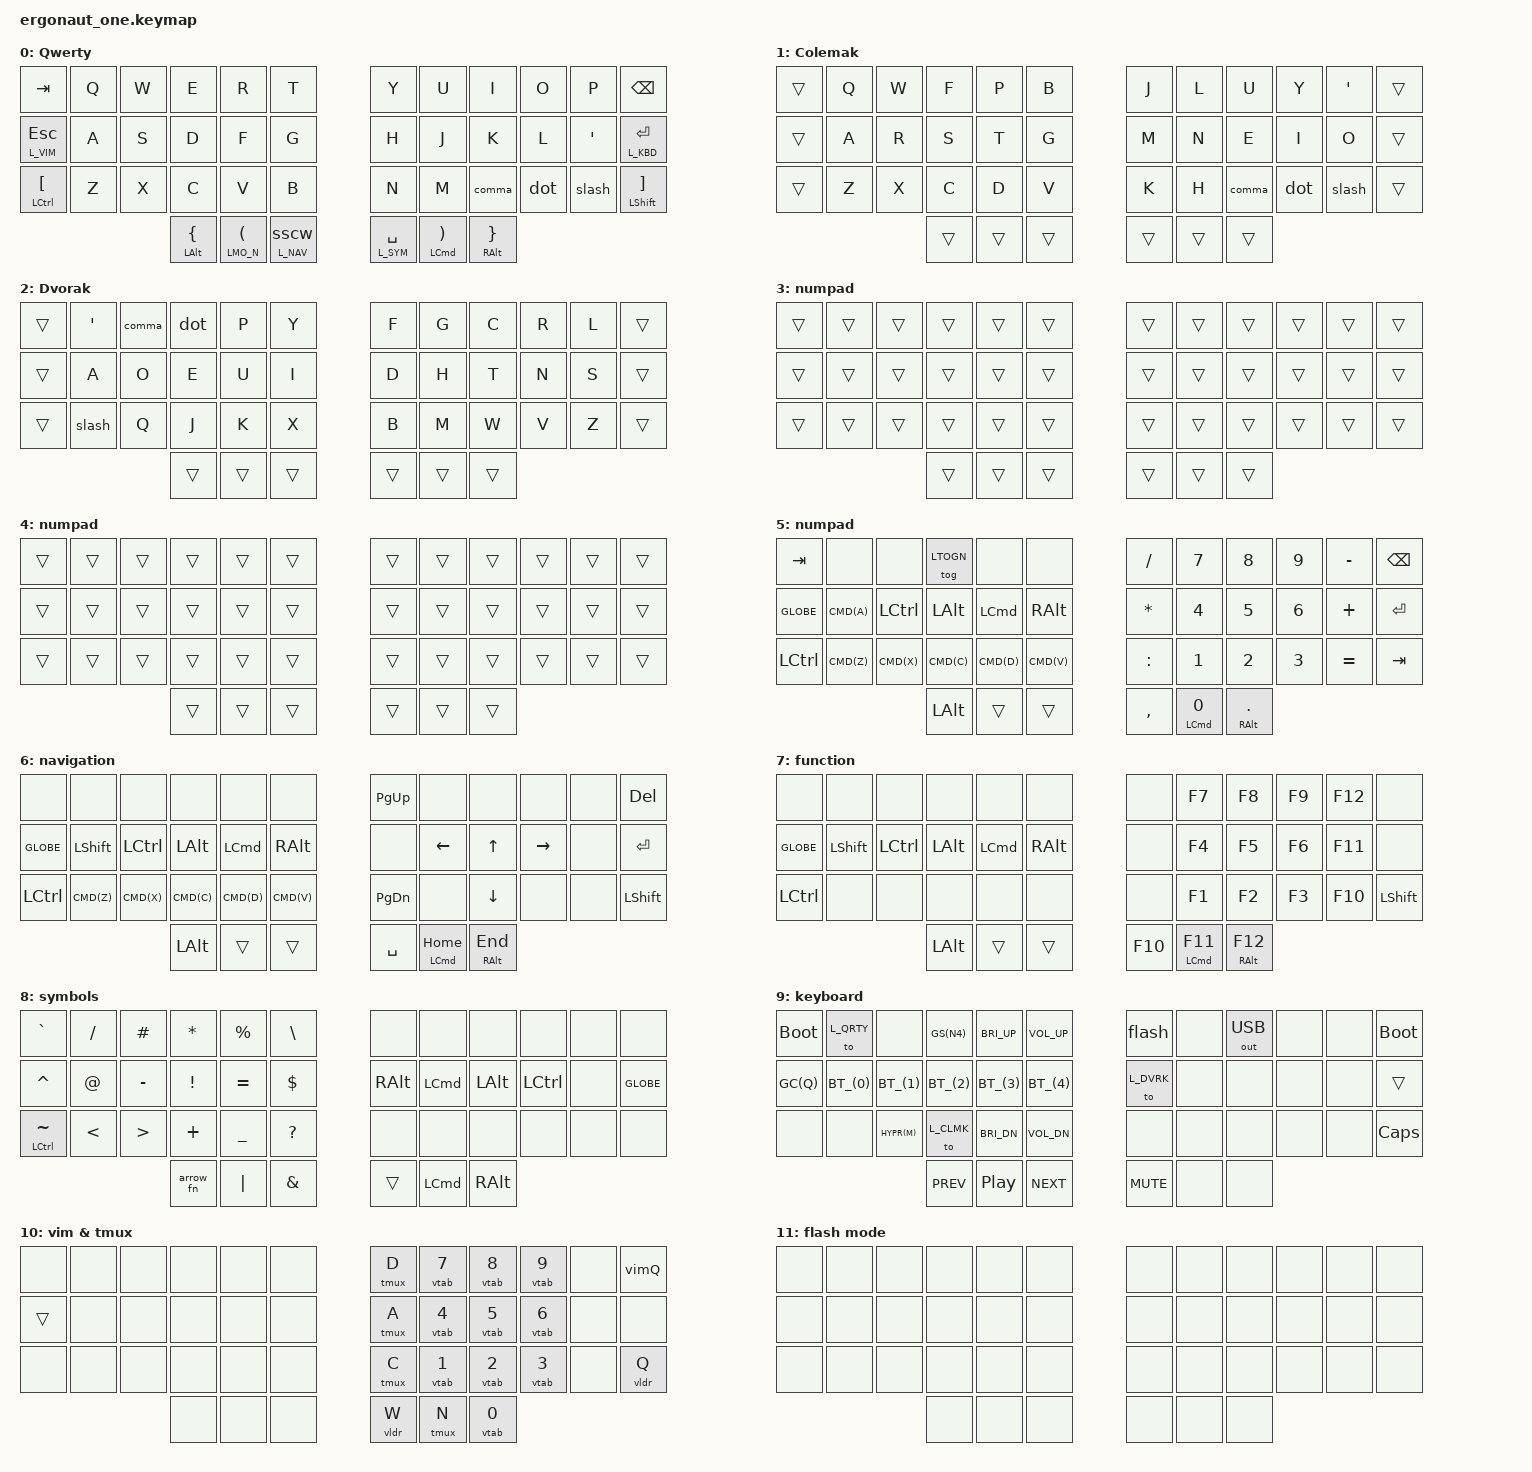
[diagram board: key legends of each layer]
#include <behaviors.dtsi>
#include <dt-bindings/zmk/bt.h>
#include <dt-bindings/zmk/keys.h>
#include <dt-bindings/zmk/outputs.h>

#define L_QRTY 0
#define L_CLMK 1
#define L_DVRK 2
#define LMO_N  3
#define LTOGN  4
#define L_NUM  5
#define L_NAV  6
#define L_FNC  7
#define L_SYM  8
#define L_KBD  9
#define L_VIM  10
#define L_BOOT 11

// transparent and none shortcuts
#define I___I &trans
#define ___ &none

// Modifier key combinations
#define CMD(key) &kp LG(key)
#define GC(key) &kp LG(LC(key))
#define GS(key) &kp LG(LS(key))
#define HYPR(key) &kp LG(LA(LC(LS(key))))

// Macro for bluetooth connections
#define BT_(btnum) &bt_key btnum btnum

&lt { quick-tap-ms = <200>; };

&mt {
    quick-tap-ms = <200>;
    require-prior-idle-ms = <150>;
    tapping-term-ms = <300>;
    flavor = "tap-preferred";
};

&sk {
    quick-release;
    release-after-ms = <2000>;
};

&caps_word { continue-list = <UNDERSCORE BACKSPACE DELETE MINUS>; };

/ {
    conditional_layers {
        compatible = "zmk,conditional-layers";

        function_combination {
            if-layers = <LMO_N L_NAV>;
            then-layer = <L_FNC>;
        };

        numpad_momentary {
            if-layers = <LMO_N>;
            then-layer = <L_NUM>;
        };

        numpad_toggle {
            if-layers = <LTOGN>;
            then-layer = <L_NUM>;
        };
    };

    macros {
        arrow_fn: arrow_fn {
            compatible = "zmk,behavior-macro";
            #binding-cells = <0>;
            bindings = <&kp EQUAL &kp GT &kp SPACE>;
        };

        bt_clr: bluetooth_clear_macro {
            compatible = "zmk,behavior-macro-one-param";
            #binding-cells = <1>;
            bindings =
                <&macro_param_1to1 &bt_sel MACRO_PLACEHOLDER>,
                <&bt BT_CLR>;
        };

        bt_sel: bluetooth_selection_macro {
            compatible = "zmk,behavior-macro-one-param";
            #binding-cells = <1>;
            bindings =
                <&out OUT_BLE>,
                <&macro_param_1to2 &bt BT_SEL MACRO_PLACEHOLDER>;
        };

        flash: flash {
            compatible = "zmk,behavior-macro";
            #binding-cells = <0>;
            bindings = <&to L_BOOT &bootloader>;
        };

        vtab: vtab {
            compatible = "zmk,behavior-macro-one-param";
            #binding-cells = <1>;
            bindings = <&kp ESC &macro_param_1to1 &kp MACRO_PLACEHOLDER &kp G &kp T>;
        };

        vldr: vldr {
            compatible = "zmk,behavior-macro-one-param";
            #binding-cells = <1>;
            bindings = <&kp ESCAPE &kp SPACE &macro_param_1to1 &kp MACRO_PLACEHOLDER>;
        };

        vimQ: vimQ {
            compatible = "zmk,behavior-macro";
            #binding-cells = <0>;
            bindings = <&kp ESCAPE &kp COLON &kp Q &kp EXCL &kp RET>;
        };

        tmux: tmux {
            compatible = "zmk,behavior-macro-one-param";
            #binding-cells = <1>;
            bindings = <&kp LC(B) &macro_param_1to1 &kp MACRO_PLACEHOLDER>;
        };
    };

    behaviors {
        bt_key: bluetooth_key {
            compatible = "zmk,behavior-hold-tap";
            #binding-cells = <2>;
            flavor = "tap-preferred";
            tapping-term-ms = <500>;
            bindings = <&bt_clr>, <&bt_sel>;
        };

        sscw: sscw {
            compatible = "zmk,behavior-mod-morph";
            bindings = <&sk LSHFT>, <&caps_word>;

            #binding-cells = <0>;
            mods = <(MOD_RSFT|MOD_LSFT)>;
        };

        lsscw: lsscw {
            compatible = "zmk,behavior-hold-tap";
            bindings = <&mo>, <&sscw>;

            #binding-cells = <2>;
            flavor = "balanced";
            tapping-term-ms = <200>;
        };

        comma: comma {
            compatible = "zmk,behavior-mod-morph";
            bindings = <&kp COMMA>, <&kp SEMI>;

            #binding-cells = <0>;
            mods = <(MOD_LSFT|MOD_RSFT)>;
        };

        dot: dot {
            compatible = "zmk,behavior-mod-morph";
            bindings = <&kp DOT>, <&kp COLON>;

            #binding-cells = <0>;
            mods = <(MOD_LSFT|MOD_RSFT)>;
        };

        slash: slash {
            compatible = "zmk,behavior-mod-morph";
            bindings = <&kp SLASH>, <&kp BACKSLASH>;

            #binding-cells = <0>;
            mods = <(MOD_LSFT|MOD_RSFT)>;
        };
    };

    keymap {
        compatible = "zmk,keymap";

        Qwerty {
//                       ┏━━━━━━━━━━━━━━━━━━━━━━━━━┓
            display-name = "Qwerty"                ;
//                       ┗━━━━━━━━━━━━━━━━━━━━━━━━━┛
            bindings = <
// ┏━━━━━━━┳━━━━━━━┳━━━━━━━┳━━━━━━━┳━━━━━━━┳━━━━━━━┓            ┏━━━━━━━┳━━━━━━━┳━━━━━━━┳━━━━━━━┳━━━━━━━┳━━━━━━━┓
// ┃  TAB  ┃   Q   ┃   W   ┃   E   ┃   R   ┃   T   ┃            ┃   Y   ┃   U   ┃   I   ┃   O   ┃   P   ┃ BKSPC ┃
    &kp TAB  &kp Q   &kp W   &kp E   &kp R   &kp T                &kp Y   &kp U   &kp I   &kp O   &kp P  &kp BSPC
// ┣━━━━━━━╋━━━━━━━╋━━━━━━━╋━━━━━━━╋━━━━━━━╋━━━━━━━┫            ┣━━━━━━━╋━━━━━━━╋━━━━━━━╋━━━━━━━╋━━━━━━━╋━━━━━━━┫
// ┃ESC vim┃   A   ┃   S   ┃   D   ┃   F   ┃   G   ┃            ┃   H   ┃   J   ┃   K   ┃   L   ┃  ' "  ┃RET kbd┃
 &lt L_VIM ESC &kp A &kp S   &kp D   &kp F   &kp G                &kp H   &kp J &kp K &kp L &kp SQT &lt L_KBD RET
// ┣━━━━━━━╋━━━━━━━╋━━━━━━━╋━━━━━━━╋━━━━━━━╋━━━━━━━┫            ┣━━━━━━━╋━━━━━━━╋━━━━━━━╋━━━━━━━╋━━━━━━━╋━━━━━━━┫
// ┃ [ ctrl┃   Z   ┃   X   ┃   C   ┃   V   ┃   B   ┃            ┃   N   ┃   M   ┃  , ;  ┃  . :  ┃  / \  ┃] shift┃
&mt LCTRL LBKT &kp Z &kp X   &kp C   &kp V   &kp B                &kp N   &kp M &comma &dot &slash &mt LSHFT RBKT
// ┗━━━━━━━┻━━━━━━━┻━━━━━━━┻━━━┳━━━┻━━━┳━━━┻━━━┳━━━┻━━━┓    ┏━━━┻━━━┳━━━┻━━━┳━━━┻━━━┳━━━┻━━━━━━━┻━━━━━━━┻━━━━━━━┛
//                             ┃ { opt ┃ ( num ┃ SHIFT ┃    ┃ SPACE ┃ ) cmd ┃ } alt ┃
                &mt LALT LBRC &lt LMO_N LPAR &lsscw L_NAV 0 &lt L_SYM SPC &mt LCMD RPAR &mt RALT RBRC
//                             ┗━━━━━━━┻━━━━━━━┫  nav  ┃    ┃  sym  ┣━━━━━━━┻━━━━━━━┛
//                                             ┗━━━━━━━┛    ┗━━━━━━━┛
            >;
        };

        Colemak {
//                       ┏━━━━━━━━━━━━━━━━━━━━━━━━━┓
            display-name = "Colemak"               ;
//                       ┗━━━━━━━━━━━━━━━━━━━━━━━━━┛
            bindings = <
// ┏━━━━━━━┳━━━━━━━┳━━━━━━━┳━━━━━━━┳━━━━━━━┳━━━━━━━┓            ┏━━━━━━━┳━━━━━━━┳━━━━━━━┳━━━━━━━┳━━━━━━━┳━━━━━━━┓
// ┃  TAB  ┃   Q   ┃   W   ┃   F   ┃   P   ┃   B   ┃            ┃   J   ┃   L   ┃   U   ┃   Y   ┃  ' "  ┃ BKSPC ┃
     I___I   &kp Q   &kp W   &kp F   &kp P   &kp B                &kp J   &kp L   &kp U   &kp Y  &kp SQT  I___I
// ┣━━━━━━━╋━━━━━━━╋━━━━━━━╋━━━━━━━╋━━━━━━━╋━━━━━━━┫            ┣━━━━━━━╋━━━━━━━╋━━━━━━━╋━━━━━━━╋━━━━━━━╋━━━━━━━┫
// ┃ESC vim┃   A   ┃   R   ┃   S   ┃   T   ┃   G   ┃            ┃   M   ┃   N   ┃   E   ┃   I   ┃   O   ┃RET kbd┃
     I___I   &kp A   &kp R   &kp S   &kp T   &kp G                &kp M   &kp N   &kp E   &kp I   &kp O   I___I
// ┣━━━━━━━╋━━━━━━━╋━━━━━━━╋━━━━━━━╋━━━━━━━╋━━━━━━━┫            ┣━━━━━━━╋━━━━━━━╋━━━━━━━╋━━━━━━━╋━━━━━━━╋━━━━━━━┫
// ┃ [ ctrl┃   Z   ┃   X   ┃   C   ┃   D   ┃   V   ┃            ┃   K   ┃   H   ┃  , ;  ┃  . :  ┃  / \  ┃] shift┃
     I___I   &kp Z   &kp X   &kp C   &kp D   &kp V                &kp K   &kp H   &comma  &dot    &slash  I___I
// ┗━━━━━━━┻━━━━━━━┻━━━━━━━┻━━━┳━━━┻━━━┳━━━┻━━━┳━━━┻━━━┓    ┏━━━┻━━━┳━━━┻━━━┳━━━┻━━━┳━━━┻━━━━━━━┻━━━━━━━┻━━━━━━━┛
//                             ┃ { opt ┃ ( num ┃ SHIFT ┃    ┃ SPACE ┃ ) cmd ┃ } alt ┃
                                 I___I   I___I   I___I        I___I   I___I   I___I
//                             ┗━━━━━━━┻━━━━━━━┫  nav  ┃    ┃  sym  ┣━━━━━━━┻━━━━━━━┛
//                                             ┗━━━━━━━┛    ┗━━━━━━━┛
            >;
        };

        Dvorak {
//                       ┏━━━━━━━━━━━━━━━━━━━━━━━━━┓
            display-name = "Dvorak"                ;
//                       ┗━━━━━━━━━━━━━━━━━━━━━━━━━┛
            bindings = <
// ┏━━━━━━━┳━━━━━━━┳━━━━━━━┳━━━━━━━┳━━━━━━━┳━━━━━━━┓            ┏━━━━━━━┳━━━━━━━┳━━━━━━━┳━━━━━━━┳━━━━━━━┳━━━━━━━┓
// ┃  TAB  ┃  ' "  ┃  , ;  ┃  . :  ┃   P   ┃   Y   ┃            ┃   F   ┃   G   ┃   C   ┃   R   ┃   L   ┃ BKSPC ┃
     I___I  &kp SQT  &comma  &dot    &kp P   &kp Y                &kp F   &kp G   &kp C   &kp R   &kp L   I___I
// ┣━━━━━━━╋━━━━━━━╋━━━━━━━╋━━━━━━━╋━━━━━━━╋━━━━━━━┫            ┣━━━━━━━╋━━━━━━━╋━━━━━━━╋━━━━━━━╋━━━━━━━╋━━━━━━━┫
// ┃ESC vim┃   A   ┃   O   ┃   E   ┃   U   ┃   I   ┃            ┃   D   ┃   H   ┃   T   ┃   N   ┃   S   ┃RET kbd┃
     I___I   &kp A   &kp O   &kp E   &kp U   &kp I                &kp D   &kp H   &kp T   &kp N   &kp S   I___I
// ┣━━━━━━━╋━━━━━━━╋━━━━━━━╋━━━━━━━╋━━━━━━━╋━━━━━━━┫            ┣━━━━━━━╋━━━━━━━╋━━━━━━━╋━━━━━━━╋━━━━━━━╋━━━━━━━┫
// ┃ [ ctrl┃  / \  ┃   Q   ┃   J   ┃   K   ┃   X   ┃            ┃   B   ┃   M   ┃   W   ┃   V   ┃   Z   ┃] shift┃
     I___I   &slash  &kp Q   &kp J   &kp K   &kp X                &kp B   &kp M   &kp W   &kp V   &kp Z   I___I
// ┗━━━━━━━┻━━━━━━━┻━━━━━━━┻━━━┳━━━┻━━━┳━━━┻━━━┳━━━┻━━━┓    ┏━━━┻━━━┳━━━┻━━━┳━━━┻━━━┳━━━┻━━━━━━━┻━━━━━━━┻━━━━━━━┛
//                             ┃ { opt ┃ ( num ┃ SHIFT ┃    ┃ SPACE ┃ ) cmd ┃ } alt ┃
                                 I___I   I___I   I___I        I___I   I___I   I___I
//                             ┗━━━━━━━┻━━━━━━━┫  nav  ┃    ┃  sym  ┣━━━━━━━┻━━━━━━━┛
//                                             ┗━━━━━━━┛    ┗━━━━━━━┛
            >;
        };

        num_pad {
            display-name = "numpad";
            bindings = <
                I___I I___I I___I I___I I___I I___I I___I I___I I___I I___I I___I I___I I___I I___I
                I___I I___I I___I I___I I___I I___I I___I I___I I___I I___I I___I I___I I___I I___I
                I___I I___I I___I I___I I___I I___I I___I I___I I___I I___I I___I I___I I___I I___I
            >;
        };

        numpad_toggle {
            display-name = "numpad";
            bindings = <
                I___I I___I I___I I___I I___I I___I I___I I___I I___I I___I I___I I___I I___I I___I
                I___I I___I I___I I___I I___I I___I I___I I___I I___I I___I I___I I___I I___I I___I
                I___I I___I I___I I___I I___I I___I I___I I___I I___I I___I I___I I___I I___I I___I
            >;
        };

        numpad {
//                       ┏━━━━━━━━━━━━━━━━━━━━━━━━━┓
            display-name = "numpad"                ;
//                       ┗━━━━━━━━━━━━━━━━━━━━━━━━━┛
            bindings = <
// ┏━━━━━━━┳━━━━━━━┳━━━━━━━┳━━━━━━━┳━━━━━━━┳━━━━━━━┓            ┏━━━━━━━┳━━━━━━━┳━━━━━━━┳━━━━━━━┳━━━━━━━┳━━━━━━━┓
// ┃  TAB  ┃       ┃       ┃numlock┃       ┃       ┃            ┃   /   ┃   7   ┃   8   ┃   9   ┃   -   ┃ BKSPC ┃
    &kp TAB   ___     ___ &tog LTOGN  ___     ___               &kp SLASH &kp N7 &kp N8 &kp N9 &kp MINUS &kp BSPC
// ┣━━━━━━━╋━━━━━━━╋━━━━━━━╋━━━━━━━╋━━━━━━━╋━━━━━━━┫            ┣━━━━━━━╋━━━━━━━╋━━━━━━━╋━━━━━━━╋━━━━━━━╋━━━━━━━┫
// ┃ globe ┃ cmd a ┃  ctrl ┃  opt  ┃  cmd  ┃  alt  ┃            ┃   *   ┃   4   ┃   5   ┃   6   ┃   +   ┃ ENTER ┃
&kp GLOBE CMD(A) &kp LCTRL &kp LALT &kp LCMD &kp RALT           &kp STAR  &kp N4 &kp N5 &kp N6 &kp PLUS &kp ENTER
// ┣━━━━━━━╋━━━━━━━╋━━━━━━━╋━━━━━━━╋━━━━━━━╋━━━━━━━┫            ┣━━━━━━━╋━━━━━━━╋━━━━━━━╋━━━━━━━╋━━━━━━━╋━━━━━━━┫
// ┃  ctrl ┃ cmd z ┃ cmd x ┃ cmd c ┃ cmd d ┃ cmd v ┃            ┃   :   ┃   1   ┃   2   ┃   3   ┃   =   ┃  TAB  ┃
   &kp LCTRL CMD(Z)  CMD(X)  CMD(C)  CMD(D)  CMD(V)             &kp COLON &kp N1 &kp N2 &kp N3  &kp EQUAL &kp TAB
// ┗━━━━━━━┻━━━━━━━┻━━━━━━━┻━━━┳━━━┻━━━┳━━━┻━━━┳━━━┻━━━┓    ┏━━━┻━━━┳━━━┻━━━┳━━━┻━━━┳━━━┻━━━━━━━┻━━━━━━━┻━━━━━━━┛
//                             ┃  opt  ┃  ###  ┃ SHIFT ┃    ┃   ,   ┃ 0 cmd ┃ . alt ┃
                               &kp LALT  I___I   I___I &kp COMMA &mt LCMD N0 &mt RALT DOT
//                             ┗━━━━━━━┻━━━━━━━┫  nav  ┃    ┃       ┣━━━━━━━┻━━━━━━━┛
//                                             ┗━━━━━━━┛    ┗━━━━━━━┛
            >;
        };

        navigation {
//                       ┏━━━━━━━━━━━━━━━━━━━━━━━━━┓
            display-name = "navigation"            ;
//                       ┗━━━━━━━━━━━━━━━━━━━━━━━━━┛
            bindings = <
// ┏━━━━━━━┳━━━━━━━┳━━━━━━━┳━━━━━━━┳━━━━━━━┳━━━━━━━┓            ┏━━━━━━━┳━━━━━━━┳━━━━━━━┳━━━━━━━┳━━━━━━━┳━━━━━━━┓
// ┃       ┃       ┃       ┃       ┃       ┃       ┃            ┃ Pg Up ┃       ┃       ┃       ┃       ┃  DEL  ┃
      ___     ___     ___     ___     ___     ___               &kp PG_UP  ___     ___     ___     ___   &kp DEL
// ┣━━━━━━━╋━━━━━━━╋━━━━━━━╋━━━━━━━╋━━━━━━━╋━━━━━━━┫            ┣━━━━━━━╋━━━━━━━╋━━━━━━━╋━━━━━━━╋━━━━━━━╋━━━━━━━┫
// ┃       ┃ shift ┃  ctrl ┃  opt  ┃  cmd  ┃  alt  ┃            ┃       ┃   ←   ┃   ↑   ┃   →   ┃       ┃ ENTER ┃
&kp GLOBE &kp LSHFT &kp LCTRL &kp LALT &kp LCMD &kp RALT           ___  &kp LEFT  &kp UP &kp RIGHT ___  &kp ENTER
// ┣━━━━━━━╋━━━━━━━╋━━━━━━━╋━━━━━━━╋━━━━━━━╋━━━━━━━┫            ┣━━━━━━━╋━━━━━━━╋━━━━━━━╋━━━━━━━╋━━━━━━━╋━━━━━━━┫
// ┃  ctrl ┃ cmd z ┃ cmd x ┃ cmd c ┃ cmd d ┃ cmd v ┃            ┃ Pg Dn ┃       ┃   ↓   ┃       ┃       ┃ shift ┃
   &kp LCTRL CMD(Z)  CMD(X)  CMD(C)  CMD(D)  CMD(V)             &kp PG_DN  ___   &kp DOWN  ___     ___  &kp LSHFT
// ┗━━━━━━━┻━━━━━━━┻━━━━━━━┻━━━┳━━━┻━━━┳━━━┻━━━┳━━━┻━━━┓    ┏━━━┻━━━┳━━━┻━━━┳━━━┻━━━┳━━━┻━━━━━━━┻━━━━━━━┻━━━━━━━┛
//                             ┃  opt  ┃  num  ┃  ###  ┃    ┃ SPACE ┃HOMEcmd┃END alt┃
                               &kp LALT  I___I   I___I &kp SPC &mt LCMD HOME &mt RALT END
//                             ┗━━━━━━━┻━━━━━━━┫       ┃    ┃       ┣━━━━━━━┻━━━━━━━┛
//                                             ┗━━━━━━━┛    ┗━━━━━━━┛
            >;
        };

        function {
//                       ┏━━━━━━━━━━━━━━━━━━━━━━━━━┓
            display-name = "function"              ;
//                       ┗━━━━━━━━━━━━━━━━━━━━━━━━━┛
            bindings = <
// ┏━━━━━━━┳━━━━━━━┳━━━━━━━┳━━━━━━━┳━━━━━━━┳━━━━━━━┓            ┏━━━━━━━┳━━━━━━━┳━━━━━━━┳━━━━━━━┳━━━━━━━┳━━━━━━━┓
// ┃       ┃       ┃       ┃       ┃       ┃       ┃            ┃       ┃  F7   ┃  F8   ┃  F9   ┃  F12  ┃       ┃
      ___     ___     ___     ___     ___     ___                  ___   &kp F7  &kp F8  &kp F9  &kp F12   ___
// ┣━━━━━━━╋━━━━━━━╋━━━━━━━╋━━━━━━━╋━━━━━━━╋━━━━━━━┫            ┣━━━━━━━╋━━━━━━━╋━━━━━━━╋━━━━━━━╋━━━━━━━╋━━━━━━━┫
// ┃ globe ┃ shift ┃  ctrl ┃  opt  ┃  cmd  ┃  alt  ┃            ┃       ┃  F4   ┃  F5   ┃  F6   ┃  F11  ┃       ┃
&kp GLOBE &kp LSHFT &kp LCTRL &kp LALT &kp LCMD &kp RALT           ___   &kp F4  &kp F5  &kp F6  &kp F11   ___
// ┣━━━━━━━╋━━━━━━━╋━━━━━━━╋━━━━━━━╋━━━━━━━╋━━━━━━━┫            ┣━━━━━━━╋━━━━━━━╋━━━━━━━╋━━━━━━━╋━━━━━━━╋━━━━━━━┫
// ┃  ctrl ┃       ┃       ┃       ┃       ┃       ┃            ┃       ┃  F1   ┃  F2   ┃  F3   ┃  F10  ┃ shift ┃
   &kp LCTRL  ___     ___     ___     ___     ___                  ___   &kp F1  &kp F2  &kp F3  &kp F10 &kp LSHFT
// ┗━━━━━━━┻━━━━━━━┻━━━━━━━┻━━━┳━━━┻━━━┳━━━┻━━━┳━━━┻━━━┓    ┏━━━┻━━━┳━━━┻━━━┳━━━┻━━━┳━━━┻━━━━━━━┻━━━━━━━┻━━━━━━━┛
//                             ┃  opt  ┃  ###  ┃  ###  ┃    ┃  F10  ┃F11 cmd┃F12 alt┃
                               &kp LALT  I___I   I___I  &kp F10 &mt LCMD F11 &mt RALT F12
//                             ┗━━━━━━━┻━━━━━━━┫       ┃    ┃       ┣━━━━━━━┻━━━━━━━┛
//                                             ┗━━━━━━━┛    ┗━━━━━━━┛
            >;
        };

        symbols {
//                       ┏━━━━━━━━━━━━━━━━━━━━━━━━━┓
            display-name = "symbols"               ;
//                       ┗━━━━━━━━━━━━━━━━━━━━━━━━━┛
            bindings = <
// ┏━━━━━━━┳━━━━━━━┳━━━━━━━┳━━━━━━━┳━━━━━━━┳━━━━━━━┓            ┏━━━━━━━┳━━━━━━━┳━━━━━━━┳━━━━━━━┳━━━━━━━┳━━━━━━━┓
// ┃   `   ┃   /   ┃   #   ┃   *   ┃   %   ┃   \   ┃            ┃       ┃       ┃       ┃       ┃       ┃       ┃
&kp GRAVE &kp SLASH &kp HASH &kp STAR &kp PRCNT &kp BSLH           ___     ___     ___     ___     ___     ___
// ┣━━━━━━━╋━━━━━━━╋━━━━━━━╋━━━━━━━╋━━━━━━━╋━━━━━━━┫            ┣━━━━━━━╋━━━━━━━╋━━━━━━━╋━━━━━━━╋━━━━━━━╋━━━━━━━┫
// ┃   ^   ┃   @   ┃   -   ┃   !   ┃   =   ┃   $   ┃            ┃  alt  ┃  cmd  ┃  opt  ┃  ctrl ┃       ┃ globe ┃
&kp CARET &kp AT &kp MINUS &kp EXCL &kp EQUAL &kp DLLR         &kp RALT &kp LCMD &kp LALT &kp LCTRL ___ &kp GLOBE
// ┣━━━━━━━╋━━━━━━━╋━━━━━━━╋━━━━━━━╋━━━━━━━╋━━━━━━━┫            ┣━━━━━━━╋━━━━━━━╋━━━━━━━╋━━━━━━━╋━━━━━━━╋━━━━━━━┫
// ┃ ~ ctrl┃   <   ┃   >   ┃   +   ┃   _   ┃   ?   ┃            ┃       ┃       ┃       ┃       ┃       ┃       ┃
&mt LCTRL TILDE &kp LT &kp GT &kp PLUS &kp UNDER &kp QMARK         ___     ___     ___     ___     ___     ___
// ┗━━━━━━━┻━━━━━━━┻━━━━━━━┻━━━┳━━━┻━━━┳━━━┻━━━┳━━━┻━━━┓    ┏━━━┻━━━┳━━━┻━━━┳━━━┻━━━┳━━━┻━━━━━━━┻━━━━━━━┻━━━━━━━┛
//                             ┃  =>   ┃   |   ┃   &   ┃    ┃  ###  ┃  cmd  ┃  alt  ┃
                              &arrow_fn &kp PIPE &kp AMPS     I___I &kp LCMD &kp RALT
//                             ┗━━━━━━━┻━━━━━━━┫       ┃    ┃       ┣━━━━━━━┻━━━━━━━┛
//                                             ┗━━━━━━━┛    ┗━━━━━━━┛
            >;
        };

        keyboard {
//                       ┏━━━━━━━━━━━━━━━━━━━━━━━━━┓
            display-name = "keyboard"              ;
//                       ┗━━━━━━━━━━━━━━━━━━━━━━━━━┛
            bindings = <
// ┏━━━━━━━━━┳━━━━━━━━━┳━━━━━━━━━┳━━━━━━━━━┳━━━━━━━━━┳━━━━━━━━━┓             ┏━━━━━━━┳━━━━━━━┳━━━━━━━┳━━━━━━━┳━━━━━━━┳━━━━━━━┓
// ┃   boot  ┃  Qwerty ┃         ┃ scrn cp ┃  bri +  ┃  vol +  ┃             ┃ dongle┃       ┃  USB  ┃       ┃       ┃ boot  ┃
  &bootloader &to L_QRTY   ___  GS(N4) &kp C_BRI_UP &kp C_VOL_UP              &flash    ___ &out OUT_USB ___    ___  &bootloader
// ┣━━━━━━━━━╋━━━━━━━━━╋━━━━━━━━━╋━━━━━━━━━╋━━━━━━━━━╋━━━━━━━━━┫             ┣━━━━━━━╋━━━━━━━╋━━━━━━━╋━━━━━━━╋━━━━━━━╋━━━━━━━┫
// ┃ scrn lk ┃  BT 1   ┃  BT 2   ┃  BT 3   ┃  BT 4   ┃  BT 5   ┃             ┃ Dvorak┃       ┃       ┃       ┃       ┃  ###  ┃
      GC(Q)     BT_(0)    BT_(1)    BT_(2)    BT_(3)    BT_(4)               &to L_DVRK ___     ___     ___     ___    I___I
// ┣━━━━━━━━━╋━━━━━━━━━╋━━━━━━━━━╋━━━━━━━━━╋━━━━━━━━━╋━━━━━━━━━┫             ┣━━━━━━━╋━━━━━━━╋━━━━━━━╋━━━━━━━╋━━━━━━━╋━━━━━━━┫
// ┃         ┃         ┃mic mute ┃ Colemak ┃  bri -  ┃  vol -  ┃             ┃       ┃       ┃       ┃       ┃       ┃  CAPS ┃
       ___       ___   HYPR(M) &to L_CLMK &kp C_BRI_DN &kp C_VOL_DN             ___     ___     ___     ___     ___  &kp CAPS
// ┗━━━━━━━━━┻━━━━━━━━━┻━━━━━━━━━┻━━━━┳━━━━┻━━━━┳━━━━┻━━━━┳━━━━┻━━━━┓    ┏━━━┻━━━┳━━━┻━━━┳━━━┻━━━┳━━━┻━━━━━━━┻━━━━━━━┻━━━━━━━┛
//                                    ┃  prev   ┃  play   ┃  next   ┃    ┃ mute  ┃       ┃       ┃
                               &kp C_PREV &kp C_PLAY_PAUSE &kp C_NEXT    &kp K_MUTE ___     ___
//                                    ┗━━━━━━━━━┻━━━━━━━━━┫         ┃    ┃       ┣━━━━━━━┻━━━━━━━┛
//                                                        ┗━━━━━━━━━┛    ┗━━━━━━━┛
            >;
        };

        vim {
//                       ┏━━━━━━━━━━━━━━━━━━━━━━━━━┓
            display-name = "vim & tmux"            ;
//                       ┗━━━━━━━━━━━━━━━━━━━━━━━━━┛
            bindings = <
// ┏━━━━━━━┳━━━━━━━┳━━━━━━━┳━━━━━━━┳━━━━━━━┳━━━━━━━┓            ┏━━━━━━━┳━━━━━━━┳━━━━━━━┳━━━━━━━┳━━━━━━━┳━━━━━━━┓
// ┃       ┃       ┃       ┃       ┃       ┃       ┃            ┃detach ┃ tab 7 ┃ tab 8 ┃ tab 9 ┃       ┃ quit! ┃
      ___     ___     ___     ___     ___     ___               &tmux D &vtab N7 &vtab N8 &vtab N9 ___    &vimQ
// ┣━━━━━━━╋━━━━━━━╋━━━━━━━╋━━━━━━━╋━━━━━━━╋━━━━━━━┫            ┣━━━━━━━╋━━━━━━━╋━━━━━━━╋━━━━━━━╋━━━━━━━╋━━━━━━━┫
// ┃  ###  ┃       ┃       ┃       ┃       ┃       ┃            ┃rename ┃ tab 4 ┃ tab 5 ┃ tab 6 ┃       ┃       ┃
     I___I    ___     ___     ___     ___     ___               &tmux A &vtab N4 &vtab N5 &vtab N6 ___     ___
// ┣━━━━━━━╋━━━━━━━╋━━━━━━━╋━━━━━━━╋━━━━━━━╋━━━━━━━┫            ┣━━━━━━━╋━━━━━━━╋━━━━━━━╋━━━━━━━╋━━━━━━━╋━━━━━━━┫
// ┃       ┃       ┃       ┃       ┃       ┃       ┃            ┃  new  ┃ tab 1 ┃ tab 2 ┃ tab 3 ┃       ┃  exit ┃
      ___     ___     ___     ___     ___     ___               &tmux C &vtab N1 &vtab N2 &vtab N3 ___   &vldr Q
// ┗━━━━━━━┻━━━━━━━┻━━━━━━━┻━━━┳━━━┻━━━┳━━━┻━━━┳━━━┻━━━┓    ┏━━━┻━━━┳━━━┻━━━┳━━━┻━━━┳━━━┻━━━━━━━┻━━━━━━━┻━━━━━━━┛
//                             ┃       ┃       ┃       ┃    ┃  save ┃ next  ┃ tab 10┃
                                  ___     ___     ___        &vldr W &tmux N &vtab N0
//                             ┗━━━━━━━┻━━━━━━━┫       ┃    ┃       ┣━━━━━━━┻━━━━━━━┛
//                                             ┗━━━━━━━┛    ┗━━━━━━━┛
            >;
        };

        bootloader {
            display-name = "flash mode";
            bindings = <
                ___ ___ ___ ___ ___ ___ ___ ___ ___ ___ ___ ___ ___ ___ ___ ___ ___ ___ ___ ___ ___
                ___ ___ ___ ___ ___ ___ ___ ___ ___ ___ ___ ___ ___ ___ ___ ___ ___ ___ ___ ___ ___
            >;
        };
    };
};

// vim: expandtab softtabstop=4 shiftwidth=4 filetype=devicetree
